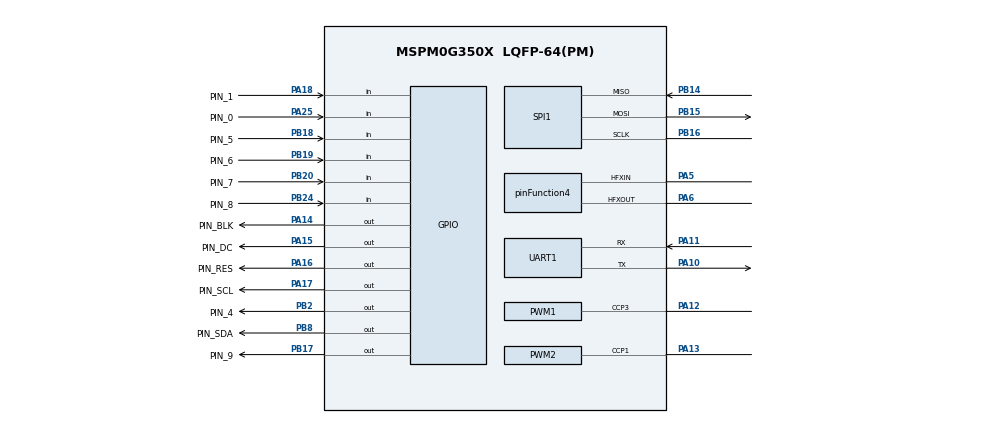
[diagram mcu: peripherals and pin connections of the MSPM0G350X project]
/**
 * @cliArgs --device "MSPM0G350X" --part "Default" --package "LQFP-64(PM)" --product "mspm0_sdk@2.10.00.04"
 * @versions {"tool":"1.27.1+4634"}
 */

/**
 * Import the modules used in this configuration.
 */
const ADC12   = scripting.addModule("/ti/driverlib/ADC12", {}, false);
const ADC121  = ADC12.addInstance();
const DMA     = scripting.addModule("/ti/driverlib/DMA");
const GPIO    = scripting.addModule("/ti/driverlib/GPIO", {}, false);
const GPIO1   = GPIO.addInstance();
const GPIO2   = GPIO.addInstance();
const GPIO3   = GPIO.addInstance();
const PWM     = scripting.addModule("/ti/driverlib/PWM", {}, false);
const PWM1    = PWM.addInstance();
const PWM2    = PWM.addInstance();
const SPI     = scripting.addModule("/ti/driverlib/SPI", {}, false);
const SPI1    = SPI.addInstance();
const SYSCTL  = scripting.addModule("/ti/driverlib/SYSCTL");
const SYSTICK = scripting.addModule("/ti/driverlib/SYSTICK");
const TIMER   = scripting.addModule("/ti/driverlib/TIMER", {}, false);
const TIMER1  = TIMER.addInstance();
const UART    = scripting.addModule("/ti/driverlib/UART", {}, false);
const UART1   = UART.addInstance();

/**
 * Write custom configuration values to the imported modules.
 */
const divider9       = system.clockTree["UDIV"];
divider9.divideValue = 2;

const mux4       = system.clockTree["EXHFMUX"];
mux4.inputSelect = "EXHFMUX_XTAL";

const mux8       = system.clockTree["HSCLKMUX"];
mux8.inputSelect = "HSCLKMUX_SYSPLL2X";

const mux12       = system.clockTree["SYSPLLMUX"];
mux12.inputSelect = "zSYSPLLMUX_HFCLK";

const pinFunction4                        = system.clockTree["HFXT"];
pinFunction4.inputFreq                    = 40;
pinFunction4.enable                       = true;
pinFunction4.peripheral.$assign           = "SYSCTL";
pinFunction4.peripheral.hfxInPin.$assign  = "PA5";
pinFunction4.peripheral.hfxOutPin.$assign = "PA6";

ADC121.$name                             = "ADC12_0";
ADC121.sampClkDiv                        = "DL_ADC12_CLOCK_DIVIDE_8";
ADC121.configureDMA                      = true;
ADC121.samplingOperationMode             = "sequence";
ADC121.repeatMode                        = true;
ADC121.enableFIFO                        = true;
ADC121.adcMem1chansel                    = "DL_ADC12_INPUT_CHAN_1";
ADC121.endAdd                            = 1;
ADC121.powerDownMode                     = "DL_ADC12_POWER_DOWN_MODE_MANUAL";
ADC121.enabledDMATriggers                = ["DL_ADC12_DMA_MEM0_RESULT_LOADED"];
ADC121.enabledInterrupts                 = ["DL_ADC12_INTERRUPT_DMA_DONE"];
ADC121.sampleTime0                       = "1 ms";
ADC121.sampCnt                           = 1;
ADC121.adcPin0Config.$name               = "ti_driverlib_gpio_GPIOPinGeneric1";
ADC121.DMA_CHANNEL.$name                 = "DMA_CH0";
ADC121.DMA_CHANNEL.addressMode           = "f2b";
ADC121.DMA_CHANNEL.configureTransferSize = true;
ADC121.DMA_CHANNEL.transferMode          = "FULL_CH_REPEAT_BLOCK";
ADC121.DMA_CHANNEL.transferSize          = 10;
ADC121.DMA_CHANNEL.peripheral.$assign    = "DMA_CH0";
ADC121.peripheral.$assign                = "ADC0";
ADC121.peripheral.adcPin0.$assign        = "PA27";
ADC121.peripheral.adcPin1.$assign        = "PA26";
ADC121.adcPin1Config.$name               = "ti_driverlib_gpio_GPIOPinGeneric2";

const Board = scripting.addModule("/ti/driverlib/Board", {}, false);

GPIO1.$name                              = "GPIO_GRP_0";
GPIO1.port                               = "PORTA";
GPIO1.associatedPins.create(2);
GPIO1.associatedPins[0].$name            = "PIN_0";
GPIO1.associatedPins[0].assignedPin      = "25";
GPIO1.associatedPins[0].direction        = "INPUT";
GPIO1.associatedPins[0].internalResistor = "PULL_UP";
GPIO1.associatedPins[0].pin.$assign      = "PA25";
GPIO1.associatedPins[1].$name            = "PIN_1";
GPIO1.associatedPins[1].assignedPin      = "18";
GPIO1.associatedPins[1].direction        = "INPUT";
GPIO1.associatedPins[1].pin.$assign      = "PA18";

GPIO2.$name                              = "GPIO_GRP_1";
GPIO2.port                               = "PORTB";
GPIO2.associatedPins.create(6);
GPIO2.associatedPins[0].$name            = "PIN_4";
GPIO2.associatedPins[0].assignedPin      = "2";
GPIO2.associatedPins[0].pin.$assign      = "PB2";
GPIO2.associatedPins[1].$name            = "PIN_5";
GPIO2.associatedPins[1].assignedPin      = "18";
GPIO2.associatedPins[1].direction        = "INPUT";
GPIO2.associatedPins[1].internalResistor = "PULL_UP";
GPIO2.associatedPins[1].pin.$assign      = "PB18";
GPIO2.associatedPins[2].$name            = "PIN_6";
GPIO2.associatedPins[2].assignedPin      = "19";
GPIO2.associatedPins[2].direction        = "INPUT";
GPIO2.associatedPins[2].internalResistor = "PULL_UP";
GPIO2.associatedPins[2].pin.$assign      = "PB19";
GPIO2.associatedPins[3].$name            = "PIN_7";
GPIO2.associatedPins[3].direction        = "INPUT";
GPIO2.associatedPins[3].assignedPin      = "20";
GPIO2.associatedPins[3].internalResistor = "PULL_UP";
GPIO2.associatedPins[3].pin.$assign      = "PB20";
GPIO2.associatedPins[4].$name            = "PIN_8";
GPIO2.associatedPins[4].assignedPin      = "24";
GPIO2.associatedPins[4].direction        = "INPUT";
GPIO2.associatedPins[4].internalResistor = "PULL_UP";
GPIO2.associatedPins[4].pin.$assign      = "PB24";
GPIO2.associatedPins[5].$name            = "PIN_9";
GPIO2.associatedPins[5].assignedPin      = "17";
GPIO2.associatedPins[5].pin.$assign      = "PB17";

GPIO3.$name                          = "GPIO_TFT";
GPIO3.associatedPins.create(5);
GPIO3.associatedPins[0].$name        = "PIN_SCL";
GPIO3.associatedPins[0].initialValue = "SET";
GPIO3.associatedPins[0].pin.$assign  = "PA17";
GPIO3.associatedPins[1].$name        = "PIN_SDA";
GPIO3.associatedPins[1].initialValue = "SET";
GPIO3.associatedPins[1].pin.$assign  = "PB8";
GPIO3.associatedPins[2].$name        = "PIN_RES";
GPIO3.associatedPins[2].pin.$assign  = "PA16";
GPIO3.associatedPins[3].$name        = "PIN_DC";
GPIO3.associatedPins[3].pin.$assign  = "PA15";
GPIO3.associatedPins[4].$name        = "PIN_BLK";
GPIO3.associatedPins[4].pin.$assign  = "PA14";

PWM1.$name                      = "PWM_0";
PWM1.ccIndex                    = [3];
PWM1.timerCount                 = 4000;
PWM1.pwmMode                    = "EDGE_ALIGN_UP";
PWM1.clockDivider               = 2;
PWM1.clockPrescale              = 10;
PWM1.peripheral.ccp3Pin.$assign = "PA12";
PWM1.PWM_CHANNEL_3.$name        = "ti_driverlib_pwm_PWMTimerCC0";
PWM1.PWM_CHANNEL_3.dutyCycle    = 50;
PWM1.ccp3PinConfig.$name        = "ti_driverlib_gpio_GPIOPinGeneric0";

PWM2.$name                      = "PWM_1";
PWM2.timerCount                 = 4000;
PWM2.ccIndex                    = [1];
PWM2.pwmMode                    = "EDGE_ALIGN_UP";
PWM2.clockPrescale              = 10;
PWM2.ccp1PinConfig.$name        = "ti_driverlib_gpio_GPIOPinGeneric7";
PWM2.peripheral.$assign         = "TIMG0";
PWM2.peripheral.ccp1Pin.$assign = "PA13";
PWM2.PWM_CHANNEL_1.$name        = "ti_driverlib_pwm_PWMTimerCC1";
PWM2.PWM_CHANNEL_1.dutyCycle    = 50;

SPI1.$name                                 = "SPI_0";
SPI1.rxFifoThreshold                       = "DL_SPI_RX_FIFO_LEVEL_ONE_FRAME";
SPI1.txFifoThreshold                       = "DL_SPI_TX_FIFO_LEVEL_ONE_FRAME";
SPI1.enabledInterrupts                     = ["DMA_DONE_RX","DMA_DONE_TX","IDLE","TX"];
SPI1.enabledDMAEvent1Triggers              = "DL_SPI_DMA_INTERRUPT_RX";
SPI1.enabledDMAEvent2Triggers              = "DL_SPI_DMA_INTERRUPT_TX";
SPI1.peripheral.$assign                    = "SPI1";
SPI1.peripheral.sclkPin.$assign            = "PB16";
SPI1.peripheral.mosiPin.$assign            = "PB15";
SPI1.peripheral.misoPin.$assign            = "PB14";
SPI1.sclkPinConfig.$name                   = "ti_driverlib_gpio_GPIOPinGeneric3";
SPI1.mosiPinConfig.$name                   = "ti_driverlib_gpio_GPIOPinGeneric4";
SPI1.misoPinConfig.$name                   = "ti_driverlib_gpio_GPIOPinGeneric5";
SPI1.cs0PinConfig.$name                    = "ti_driverlib_gpio_GPIOPinGeneric6";
SPI1.DMA_CHANNEL_EVENT1.$name              = "DMA_CH1";
SPI1.DMA_CHANNEL_EVENT1.srcLength          = "BYTE";
SPI1.DMA_CHANNEL_EVENT1.dstLength          = "BYTE";
SPI1.DMA_CHANNEL_EVENT1.addressMode        = "f2b";
SPI1.DMA_CHANNEL_EVENT1.peripheral.$assign = "DMA_CH2";
SPI1.DMA_CHANNEL_EVENT2.$name              = "DMA_CH2";
SPI1.DMA_CHANNEL_EVENT2.srcLength          = "BYTE";
SPI1.DMA_CHANNEL_EVENT2.dstLength          = "BYTE";
SPI1.DMA_CHANNEL_EVENT2.addressMode        = "b2f";
SPI1.DMA_CHANNEL_EVENT2.peripheral.$assign = "DMA_CH1";

SYSCTL.forceDefaultClkConfig = true;
SYSCTL.clockTreeEn           = true;

SYSTICK.periodEnable    = true;
SYSTICK.interruptEnable = true;
SYSTICK.period          = 80000;

TIMER1.$name              = "TIMER_0";
TIMER1.timerPeriod        = "1 ms";
TIMER1.interrupts         = ["ZERO"];
TIMER1.timerClkPrescale   = 40;
TIMER1.timerClkDiv        = 2;
TIMER1.peripheral.$assign = "TIMA1";

UART1.$name                             = "UART_0";
UART1.targetBaudRate                    = 921600;
UART1.enableFIFO                        = true;
UART1.rxFifoThreshold                   = "DL_UART_RX_FIFO_LEVEL_ONE_ENTRY";
UART1.txFifoThreshold                   = "DL_UART_TX_FIFO_LEVEL_ONE_ENTRY";
UART1.enabledDMARXTriggers              = "DL_UART_DMA_INTERRUPT_RX";
UART1.enabledDMATXTriggers              = "DL_UART_DMA_INTERRUPT_TX";
UART1.enabledInterrupts                 = ["DMA_DONE_RX","DMA_DONE_TX","EOT_DONE","RX"];
UART1.peripheral.rxPin.$assign          = "PA11";
UART1.peripheral.txPin.$assign          = "PA10";
UART1.txPinConfig.$name                 = "ti_driverlib_gpio_GPIOPinGeneric8";
UART1.rxPinConfig.$name                 = "ti_driverlib_gpio_GPIOPinGeneric9";
UART1.DMA_CHANNEL_RX.$name              = "DMA_CH3";
UART1.DMA_CHANNEL_RX.srcLength          = "BYTE";
UART1.DMA_CHANNEL_RX.dstLength          = "BYTE";
UART1.DMA_CHANNEL_RX.addressMode        = "f2b";
UART1.DMA_CHANNEL_RX.peripheral.$assign = "DMA_CH4";
UART1.DMA_CHANNEL_TX.$name              = "DMA_CH4";
UART1.DMA_CHANNEL_TX.addressMode        = "b2f";
UART1.DMA_CHANNEL_TX.srcLength          = "BYTE";
UART1.DMA_CHANNEL_TX.dstLength          = "BYTE";
UART1.DMA_CHANNEL_TX.peripheral.$assign = "DMA_CH3";

/**
 * Pinmux solution for unlocked pins/peripherals. This ensures that minor changes to the automatic solver in a future
 * version of the tool will not impact the pinmux you originally saw.  These lines can be completely deleted in order to
 * re-solve from scratch.
 */
Board.peripheral.$suggestSolution          = "DEBUGSS";
Board.peripheral.swclkPin.$suggestSolution = "PA20";
Board.peripheral.swdioPin.$suggestSolution = "PA19";
PWM1.peripheral.$suggestSolution           = "TIMA0";
SPI1.peripheral.cs0Pin.$suggestSolution    = "PA2";
UART1.peripheral.$suggestSolution          = "UART0";
